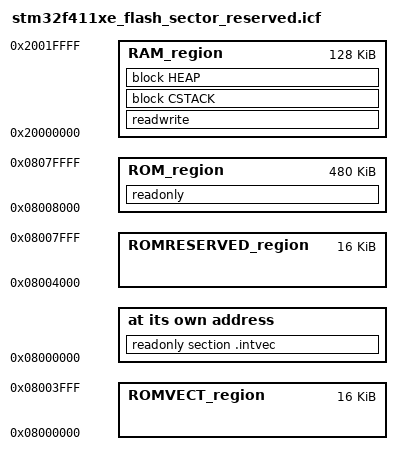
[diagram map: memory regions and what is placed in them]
/*###ICF### Section handled by ICF editor, don't touch! ****/
/*-Editor annotation file-*/
/* IcfEditorFile="$TOOLKIT_DIR$\config\ide\IcfEditor\cortex_v1_0.xml" */
/*-Specials-*/
define symbol __ICFEDIT_intvec_start__ = 0x08000000;
/*-Memory Regions-*/
define symbol __ICFEDIT_region_ROMVECT_start__      = 0x08000000;
define symbol __ICFEDIT_region_ROMVECT_end__        = 0x08003FFF;
define symbol __ICFEDIT_region_ROMRESERVED_start__  = 0x08004000;
define symbol __ICFEDIT_region_ROMRESERVED_end__    = 0x08007FFF;
define symbol __ICFEDIT_region_ROM_start__          = 0x08008000;
define symbol __ICFEDIT_region_ROM_end__            = 0x0807FFFF;
define symbol __ICFEDIT_region_RAM_start__          = 0x20000000;
define symbol __ICFEDIT_region_RAM_end__            = 0x2001FFFF;
/*-Sizes-*/
define symbol __ICFEDIT_size_cstack__      = 0x800;
define symbol __ICFEDIT_size_heap__        = 0x400;
define symbol __ICFEDIT_size_ROMRESERVED__ = 0x4000;
/*-Reserved Area-*/
define symbol __start_sector_reserved = __ICFEDIT_region_ROMRESERVED_start__;
define symbol __end_sector_reserved   = __ICFEDIT_region_ROMRESERVED_end__;
/**** End of ICF editor section. ###ICF###*/

export symbol __start_sector_reserved;
export symbol __end_sector_reserved;

define memory mem with size = 4G;
define region ROMVECT_region      = mem:[from __ICFEDIT_region_ROMVECT_start__     to __ICFEDIT_region_ROMVECT_end__];
define region ROMRESERVED_region  = mem:[from __ICFEDIT_region_ROMRESERVED_start__ to __ICFEDIT_region_ROMRESERVED_end__];
define region ROM_region          = mem:[from __ICFEDIT_region_ROM_start__         to __ICFEDIT_region_ROM_end__];
define region RAM_region          = mem:[from __ICFEDIT_region_RAM_start__         to __ICFEDIT_region_RAM_end__];

define block CSTACK    with alignment = 8, size = __ICFEDIT_size_cstack__   { };
define block HEAP      with alignment = 8, size = __ICFEDIT_size_heap__     { };

initialize by copy { readwrite };
do not initialize  { section .noinit };

place at address mem:__ICFEDIT_intvec_start__ { readonly section .intvec };

place in ROM_region         { readonly };
place in RAM_region         { readwrite,
                              block CSTACK, block HEAP };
